# SPC1169 register map
File version: 2022071043481212
CPU: cm4 r1p0, little endian, no MPU, FPU, 4 interrupt priority bits
Registers are 32-bit, read-write, reset 0x0 unless marked. A register's access mark holds for its fields unless they carry their own. Offsets are from the block's base; [hi:lo] are bit positions; lines under a group give offsets from that group; {n}, {i} and the like mark numbered series; 'fields as' and 'values as' point back to an identical list.

## CAN
Base 0x40005400
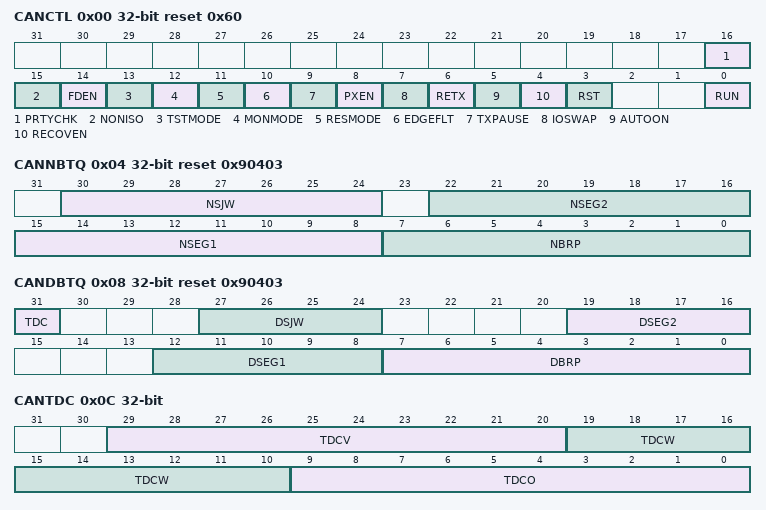
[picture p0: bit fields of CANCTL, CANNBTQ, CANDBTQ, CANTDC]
0x00 CANCTL reset 0x60 — Control Register
  [16] PRTYCHK — Parity check enable.
    0=DISABLE; 1=ENABLE
  [15] NONISO — NON-ISO CAN protocol mode. This field is writable only when CANSTS.OP is STOP.
    0=NO (Use ISO-CANFD format, which defined by ISO11898-1:2015.); 1=YES (Use NON-ISO-CANFD format, which defined by Bosch CAN2.0B and CANFD_V1.0)
  [14] FDEN — CANFD enable. This field is writable only when CANSTS.OP is STOP.
    0=DISABLE (Disable CANFD format frame.); 1=ENABLE (Enable CANFD format frame.)
  [13] TSTMODE — Test mode enable. This field is writable only when CANSTS.OP is STOP.
    0=DISABLE; 1=ENABLE
  [12] MONMODE — Monitor mode enable. This field is write 1 protected by REGKEY, and only writable when CANSTS.OP is STOP. This field can be set to 0 at any time.
    0=DISABLE; 1=ENABLE
  [11] RESMODE — Restricted mode enable. This field is write 1 protected by REGKEY, and only writable when CANSTS.OP is STOP. This field can be set to 0 at any time.
    0=DISABLE; 1=ENABLE
  [10] EDGEFLT — Edge filter enable in integration status.
    0=DISABLE; 1=ENABLE (During integration status, sample consecutive 2tq dominant will be treated as falling edge.)
  [9] TXPAUSE — Transmission pause 2 nominal bit enable.
    0=DISABLE; 1=ENABLE (After successful transmit one frame, then delay 2 nominal bit to send another frame. This make other node send lower priority message on bus without arbitration.)
  [8] PXEN — Protocol exception enable. This field is writable only when CANSTS.OP is STOP.
    0=DISABLE; 1=ENABLE
  [7] IOSWAP — Enable swap TXD/RXD Pin. This field is writable only when CANSTS.OP is STOP.
    0=DISABLE (Disable swap TXD/RXD pin.); 1=ENABLE (Enable swap TXD/RXD pin.)
  [6] RETX — Enable automatic retransmission. This field is writable only when CANSTS.OP is STOP.
    0=DISABLE (Enable automatic retransmission.); 1=ENABLE (Disable automatic retransmission of "not successful" messages.)
  [5] AUTOON — Enable auto bus on.
    0=DISABLE (The Auto-Bus-On feature is disabled.); 1=ENABLE (The Auto-Bus-On feature is enabled.)
  [4] RECOVEN — Enable bus off recovery. This field is not write protected by REGKEY.
    0=DISABLE; 1=ENABLE (After bus off: if CANCTL.AUTOON is not set, software enable this bit to start Auto-Bus-On procedure; if CANCTL.AUTOON is set, hardware start Auto-Bus-On procedure.)
  [3] RST — Software reset.
    0=DISABLE; 1=ENABLE (Force module to reset state. This bit will get cleared automatically after module reset. Note: To execute software reset, the following procedure is necessary: 1. Set CANCTL.RUN to STOP CAN communication. 2. Set CANCTL.RST bit.)
  [0] RUN — Enable module run.
    0=STOP (Stop module); 1=RUN (Run module)
0x04 CANNBTQ reset 0x90403 — Nominal Bit Timing Quatum Register
  [30:24] NSJW — Synchronization jump width of nominal bit rate. This field is writable only when CANSTS.OP is STOP.
  [22:16] NSEG2 — Time segment after the sample point of nominal bit rate. This field is writable only when CANSTS.OP is STOP.
  [15:8] NSEG1 — Time segment before the sample point of nominal bit rate. This field is writable only when CANSTS.OP is STOP.
  [7:0] NBRP — Norminal bit rate prescaler value. This field is writable only when CANSTS.OP is STOP.
0x08 CANDBTQ reset 0x90403 — Data Bit Timing Quatum Register
  [31] TDC — Transmitter delay compensation enable. This field is writable only when CANSTS.OP is STOP.
    0=DISABLE; 1=ENABLE
  [27:24] DSJW — Synchronization jump width for CANFD data bit rate. This field is writable only when CANSTS.OP is STOP.
  [19:16] DSEG2 — Time segment after the sample point for CANFD data bit rate. This field is writable only when CANSTS.OP is STOP.
  [12:8] DSEG1 — Time segment before the sample point for CANFD data bit rate. This field is writable only when CANSTS.OP is STOP.
  [7:0] DBRP — Data baud rate prescaler value. This field is writable only when CANSTS.OP is STOP.
0x0C CANTDC — Transmitter Delay Compensation Register
  [29:20] TDCV ro — Transmitter delay compensation value
  [19:10] TDCW — Transmitter delay compensation filter window length.
  [9:0] TDCO — Transmitter delay conmpensation SSP offset
0x10 CANBRDLY — Bus-Off Recovery Delay Register
  [15:0] DLY — Bus-Off recovery delay.
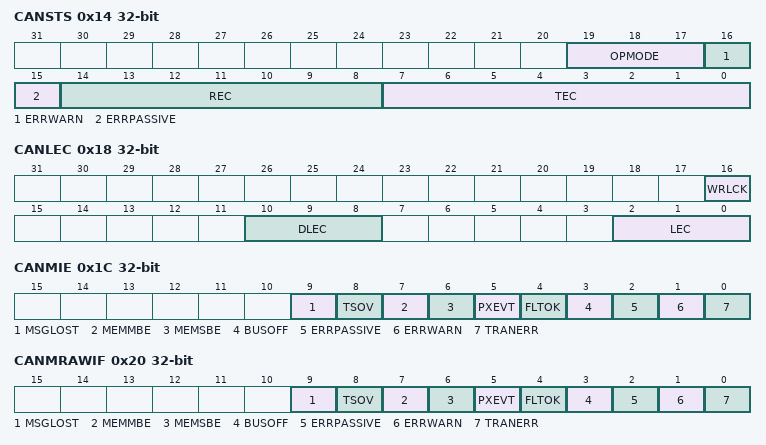
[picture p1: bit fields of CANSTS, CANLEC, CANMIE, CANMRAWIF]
0x14 CANSTS ro — Status Register
  [19:17] OPMODE — Operation mode.
    0=STOP; 1=INTEGRATION; 2=IDLE; 3=TXING; 4=RXING; 6=BUSOFF; 7=SLEEP (TODO: not implement now.)
  [16] ERRWARN — Error warning.
    0=NOT_OCCURED (Both error counters are below the error warning limit.); 1=OCCURRED (At least one of the error counters has reached the error warning limit of 96.)
  [15] ERRPASSIVE — Error passive state.
    0=NOT_OCCURED (On CAN Bus error, the CAN could send active error frames.); 1=OCCURRED (The CAN Core is in the error passive state as defined in the CAN Specification.)
  [14:8] REC — Receiver error counter.
  [7:0] TEC — Transmitter error counter.
0x18 CANLEC ro — Last Error Code Register
  [16] WRLCK — Write on locked mailbox occurred. Suggest read by byte size.
    0=NOT_OCCURED; 1=OCCURRED (Write on mailbox, which is locked by message handler and busy transfering message. Write action will be ignored.)
  [10:8] DLEC — Last error code during data phase. Suggest read by byte size.
    0=NO_ERROR; 1=STUFF_ERROR; 2=FORM_ERROR; 4=BIT1_ERROR; 5=BIT0_ERROR; 7=NO_ERROR_AFTER_READ
  [2:0] LEC — Last error code except data phase. Suggest read by byte size.
    0=NO_ERROR (This field will be cleared to '0' when a message has been transferred (reception or transmission) without error.); 1=STUFF_ERROR (More than five equal bits in a row have been detected in a part of a received message where this is not allowed.); 2=FORM_ERROR (A fixed format part of a received frame has the wrong format.); 3=ACK_ERROR (The message this CAN Core transmitted was not acknowledged by another node.); 4=BIT1_ERROR (During the transmission of a message (with the exception of the arbitration field), the device wanted to send a recessive level (bit of logical value '1'), but the monitored bus value was dominant.); 5=BIT0_ERROR (During the transmission of a message (or acknowledge bit, or active error flag, or overload flag), the device wanted to send a dominant level (logical value '0'), but the monitored bus level was recessive. Note: During Bus-Off recovery, this status is set each time a sequence of 11 recessive bits has been monitored. This enables the CPU to monitor the proceeding of the Bus-Off recovery sequence (indicating the bus is not stuck at dominant or continuously disturbed).); 6=CRC_ERROR (In a received message, the CRC check sum was incorrect. (CRC received for an incoming message does not match the calculated CRC for the received data).); 7=NO_ERROR_AFTER_READ (This field will be reset to '7' whenever the CPU reads the register.)
0x1C CANMIE — Misc Interrupt Enable Register
  [all] fields
    0=DISABLE; 1=ENABLE
  [9] MSGLOST — Message lost.
  [8] TSOV — Timestamp counter overflow.
  [7] MEMMBE — Memory multi bit error.
  [6] MEMSBE — Memory single bit error.
  [5] PXEVT — Protocol exception event.
  [4] FLTOK — Receive message identifier filter OK.
  [3] BUSOFF — Node enter bus off status.
  [2] ERRPASSIVE — Node enter error passive status
  [1] ERRWARN — Node error warning.
  [0] TRANERR — Message transfer error.
0x20 CANMRAWIF ro — Misc Raw Interrupt Flag Register
  [9] MSGLOST — Message lost.
    0=NOT_OCCURED; 1=OCCURRED
  [8] TSOV — Timestamp counter overflow.
    0=NOT_OCCURED; 1=OCCURRED
  [7] MEMMBE — Memory multi bit error.
    0=NOT_OCCURED; 1=OCCURRED
  [6] MEMSBE — Memory single bit error.
    0=NOT_OCCURED; 1=OCCURRED (Message RAM error event occurred.)
  [5] PXEVT — Protocol exception event.
    0=NOT_OCCURED; 1=OCCURRED (Protocol exception event occurred.)
  [4] FLTOK — Receive message identifier filter OK.
    0=NOT_OCCURED; 1=OCCURRED (Received message ID filter OK.)
  [3] BUSOFF — Node enter bus off status.
    0=NOT_OCCURED; 1=OCCURRED (The CAN Core enter Bus-Off state or. BIT0_ERROR occurred during Bus-Off recovery.)
  [2] ERRPASSIVE — Node enter error passive status
    0=NOT_OCCURED; 1=OCCURRED (The CAN Core enter error passive state.)
  [1] ERRWARN — Node error warning.
    0=NOT_OCCURED; 1=OCCURRED (At least one of the error counters has reached the error warning limit.)
  [0] TRANERR — Message transfer error.
    0=NOT_OCCURED; 1=OCCURRED (Message transfer error occurred.)
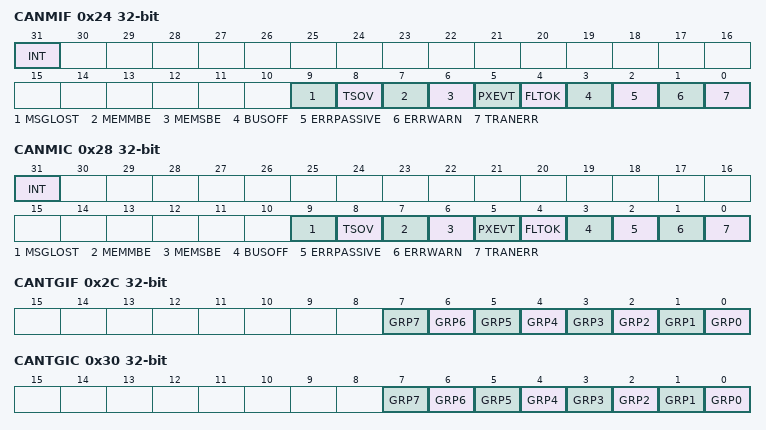
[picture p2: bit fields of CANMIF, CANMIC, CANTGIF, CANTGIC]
0x24 CANMIF ro — Misc Interrupt Flag Register
  [31] INT — Global interrupt
    0=NOT_OCCURED; 1=OCCURRED
  [9] MSGLOST — Message lost.
    0=NOT_OCCURED; 1=OCCURRED
  [8] TSOV — Timestamp counter overflow.
    0=NOT_OCCURED; 1=OCCURRED
  [7] MEMMBE — Memory multi bit error.
    values as CANMRAWIF.MEMSBE
  [6] MEMSBE — Memory single bit error.
    values as CANMRAWIF.MEMSBE
  [5] PXEVT — Protocol exception event.
    values as CANMRAWIF.PXEVT
  [4] FLTOK — Receive message identifier filter OK.
    0=NOT_OCCURED; 1=OCCURRED (Received message ID filter OK.)
  [3] BUSOFF — Node enter bus off status.
    values as CANMRAWIF.BUSOFF
  [2] ERRPASSIVE — Node enter error passive status
    values as CANMRAWIF.ERRPASSIVE
  [1] ERRWARN — Node error warning.
    values as CANMRAWIF.ERRWARN
  [0] TRANERR — Message transfer error.
    0=NOT_OCCURED; 1=OCCURRED (Message transfer error occurred.)
0x28 CANMIC — Misc Interrupt Flag Clear Register
  [all] fields
    0=NO_EFFECT; 1=CLEAR
  [31] INT — Global interrupt
  [9] MSGLOST — Message lost.
  [8] TSOV — Timestamp counter overflow.
  [7] MEMMBE — Memory multi bit error.
  [6] MEMSBE — Memory single bit error.
  [5] PXEVT — Protocol exception event.
  [4] FLTOK — Receive message identifier filter OK.
  [3] BUSOFF — Node enter bus off status.
  [2] ERRPASSIVE — Node enter error passive status
  [1] ERRWARN — Node error warning.
  [0] TRANERR — Message transfer error.
0x2C CANTGIF ro — Transfer Group Interrupt Flag Register
  [all] fields
    0=NOT_OCCURED; 1=OCCURRED
  [n] GRP{n} (n=0..7) — Transfer group {n}.
0x30 CANTGIC — Transfer Group Interrupt Flag Clear Register
  [all] fields
    0=NO_EFFECT; 1=CLEAR
  [n] GRP{n} (n=0..7) — Transfer group {n}.
0x34 CANMEMERRADDR ro — Memory Error Address Register
  [31:0] ADDR
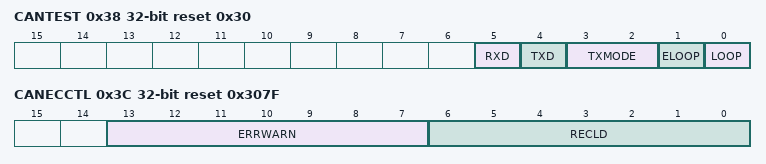
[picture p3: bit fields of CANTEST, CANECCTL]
0x38 CANTEST reset 0x30 — Test Control Register
  [5] RXD ro — Monitors the actual value of the RXD pin.
    0=LOW; 1=HIGH
  [4] TXD ro — Monitors the actual value of the TXD pin.
    0=LOW; 1=HIGH
  [3:2] TXMODE — Control of TXD Pin. Disable CANCTL.TSTMODE will reset this field.
    0=NORMAL (Normal operation, TXD pin controlled by can_core module.); 1=SEND_SP (Sample point can be monitored at TXD pin.); 2=SEND_LOW (TXD pin drives a dominant value.); 3=SEND_HIGH (TXD pin drives a recessive value.)
  [1] ELOOP — Enable external loop back mode. Disable CANCTL.TSTMODE will reset this field.
    0=DISABLE; 1=ENABLE
  [0] LOOP — Enable loop back mode. Disable CANCTL.TSTMODE will reset this field.
    0=DISABLE; 1=ENABLE
0x3C CANECCTL reset 0x307F — Error Counter Control Register
  [13:7] ERRWARN — Error warning limit value.
  [6:0] RECLD — REC load value after successfully reception one frame and REC is grater than 127.
{0x40+4i} CANTXREQ[{i}] (i=0..1) ro — Transmission Request Register
  [31:0] VAL — Transmission request bits (for all message objects). 0 No transmission has been requested for this message object. 1 The transmission of this message object is requested and is not yet done. Note: Bit 0 is for MBOX0, Bit 1 is for MBOX1, ..., Bit 63 for MBOX63.
{0x50+4i} CANMSGNEW[{i}] (i=0..1) ro — New Message Register
  [31:0] VAL — New message bits (for all message objects). 0 No new data has been written into the data portion of this message object by the message handler since the last time when this flag was cleared by the CPU. 1 The message handler or the CPU has written new data into the data portion of this message object. Note: Bit 0 is for MBOX0, Bit 1 is for MBOX1, ..., Bit 63 for MBOX63.
{0x60+4i} CANMSGIF[{i}] (i=0..1) ro — Message Transfer Done Interrupt Flag Register
  [31:0] VAL — Interrupt pending bits (for all message objects). 0 This mailbox is not the source of transfer OK interrupt. 1 This mailbox is the source of transfer OK interrupt. Note: Bit 0 is for MBOX0, Bit 1 is for MBOX1, ..., Bit 63 for MBOX63.
{0x70+4i} CANMBEN[{i}] (i=0..1) ro — Mailbox Enable Register
  [31:0] VAL — Mailbox enable bits (for all message objects). 0 This message object is ignored by the message handler. 1 This message object is configured and will be considered by the message handler. Note: Bit 0 is for MBOX0, Bit 1 is for MBOX1, ..., Bit 63 for MBOX63.
0x80 CANTSCTL — Timestamp Control Register
  [0] TSEN — Timestamp enable
    0=DISABLE; 1=ENABLE
0x84 CANTSCNT — Timestamp Counter Register
  [31:0] TSCNT — Timestamp up-counter value. Note: write will set this field. Note: Count based on sample point.
0x8C CANREGKEY reset 0x1ACCE551 — Register write-allow key register
  [31:0] KEY — Write 0x1ACCE551 to unlock protected registers.
